# PY32MD420xx register map
Vendor: Puya; Series: PY32M; File version: 1.0.0
CPU: CM0+ r0p1, little endian, no MPU, no FPU, 4 interrupt priority bits
Registers are 32-bit, read-write, reset 0x0 unless marked. A register's access mark holds for its fields unless they carry their own. Offsets are from the block's base; [hi:lo] are bit positions; lines under a group give offsets from that group; {n}, {i} and the like mark numbered series; 'fields as' and 'values as' point back to an identical list.

## ADC — Analog to Digital Converter
Base 0x40012400
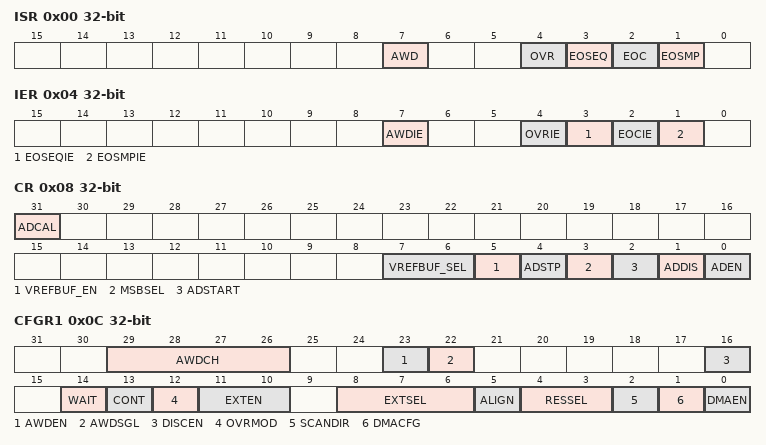
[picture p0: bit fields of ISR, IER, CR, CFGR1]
0x00 ISR — ADC interrupt and status register
  [7] AWD — ADC analog watchdog flag
  [4] OVR — ADC group regular overrun flag
  [3] EOSEQ — ADC group regular end of sequence conversions flag
  [2] EOC — ADC group regular end of unitary conversion flag
  [1] EOSMP — ADC group regular end of sampling flag
0x04 IER — ADC interrupt enable register
  [7] AWDIE — ADC analog watchdog interrupt
  [4] OVRIE — ADC group regular overrun interrupt
  [3] EOSEQIE — ADC group regular end of sequence conversions interrupt
  [2] EOCIE — ADC group regular end of unitary conversion interrupt
  [1] EOSMPIE — ADC group regular end of sampling interrupt
0x08 CR — ADC control register
  [31] ADCAL — ADC group regular conversion calibration
  [7:6] VREFBUF_SEL — ADC VrefBuffer output voltage select
    1=0; 2=1
  [5] VREFBUF_EN — ADC VrefBuffer enable
  [4] ADSTP — ADC group regular conversion stop
  [3] MSBSEL — ADC resolution highest bit conversion time control
  [2] ADSTART — ADC group regular conversion start
  [1] ADDIS — ADC disable
  [0] ADEN — ADC enable
0x0C CFGR1 — ADC configuration register 1
  [29:26] AWDCH — ADC analog watchdog monitored channel selection
    1=0; 2=1; 4=2; 8=3
  [23] AWDEN — ADC analog watchdog enable on scope ADC group regular
  [22] AWDSGL — ADC analog watchdog monitoring a single channel or all channels
  [16] DISCEN — ADC group regular sequencer discontinuous mode
  [14] WAIT — Wait conversion mode
  [13] CONT — ADC group regular continuous conversion mode
  [12] OVRMOD — ADC group regular overrun configuration
  [11:10] EXTEN — ADC group regular external trigger polarity
    1=0; 2=1
  [8:6] EXTSEL — ADC group regular external trigger source
    1=0; 2=1; 4=2
  [5] ALIGN — ADC data alignement
  [4:3] RESSEL — ADC data resolution
    1=0; 2=1
  [2] SCANDIR — Scan sequence direction
  [1] DMACFG — ADC DMA transfer configuration
  [0] DMAEN — ADC DMA transfer enable
0x10 CFGR2 — ADC configuration register 2
  [31:28] CKMODE — ADC clock mode
    1=0; 2=1; 4=2; 8=3
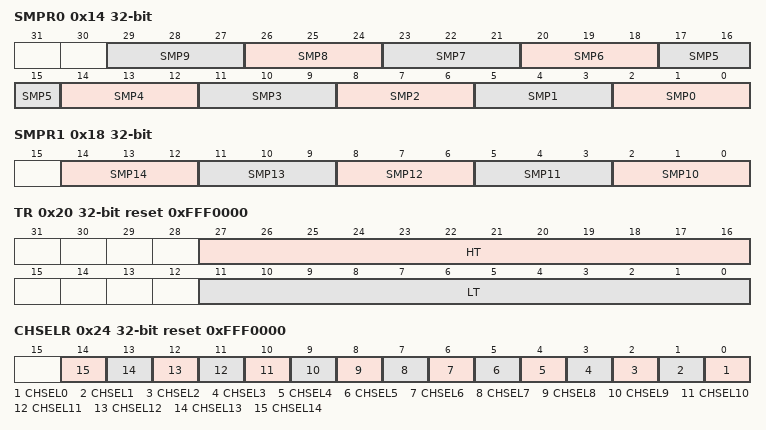
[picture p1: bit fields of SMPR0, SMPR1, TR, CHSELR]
0x14 SMPR0 — ADC sampling time register 0
  [all] fields
    1=0; 2=1; 4=2
  [3n+2:3n] SMP{n} (n=0..9) — Sampling time selection
0x18 SMPR1 — ADC sampling time register 1
  [all] fields
    1=0; 2=1; 4=2
  [3n-28:3n-30] SMP{n} (n=10..14) — Sampling time selection
0x20 TR reset 0xFFF0000 — ADC analog watchdog 1 threshold register
  [27:16] HT — ADC analog watchdog threshold high
    1=0; 2=1; 4=2; 8=3; 16=4; 32=5; 64=6; 128=7; 0x100=8; 0x200=9; 0x400=10; 0x800=11
  [11:0] LT — ADC analog watchdog threshold low
    values as HT
0x24 CHSELR reset 0xFFF0000 — ADC group regular sequencer register
  [n] CHSEL{n} (n=0..14) — Channel-{n} selection
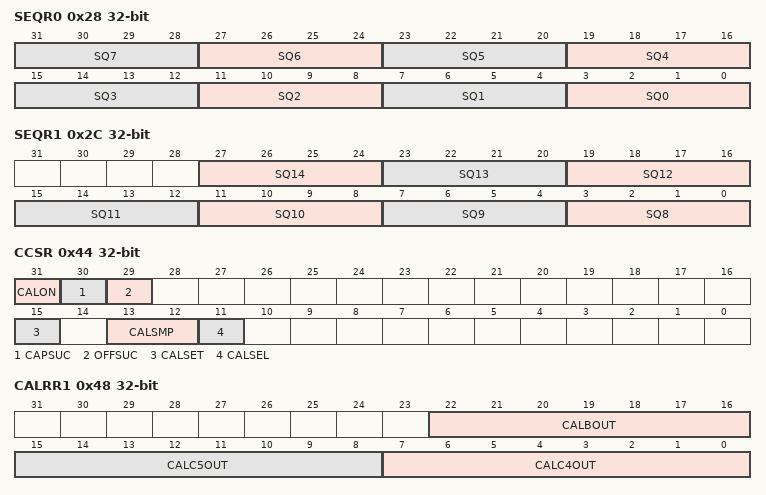
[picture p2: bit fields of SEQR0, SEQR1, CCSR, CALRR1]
0x28 SEQR0 — ADC sequence select register 0
  [all] fields
    1=0; 2=1; 4=2; 8=4
  [4n+3:4n] SQ{n} (n=0..7) — ADC sequence select
0x2C SEQR1 — ADC sequence select register 1
  [all] fields
    1=0; 2=1; 4=2; 8=4
  [4n-29:4n-32] SQ{n} (n=8..14) — ADC sequence select
0x40 DR ro — ADC group regular data register
  [15:0] DATA — ADC group regular conversion data
    1=0; 2=1; 4=2; 8=3; 16=4; 32=5; 64=6; 128=7; 0x100=8; 0x200=9; 0x400=10; 0x800=11; 0x1000=12; 0x2000=13; 0x4000=14; 0x8000=15
0x44 CCSR — ADC calibration configuration and status register
  [31] CALON ro — Calibration flag
  [30] CAPSUC — Cap calibration status flag
  [29] OFFSUC — Offset calibration status flag
  [15] CALSET — Calibration factor selection
  [13:12] CALSMP — Calibration sample time selection
    1=0; 2=1
  [11] CALSEL — Calibration contents selection
0x48 CALRR1 ro — ADC calibration result register 1
  [22:16] CALBOUT — offset result
  [15:8] CALC5OUT — C5 result
  [7:0] CALC4OUT — C4 result
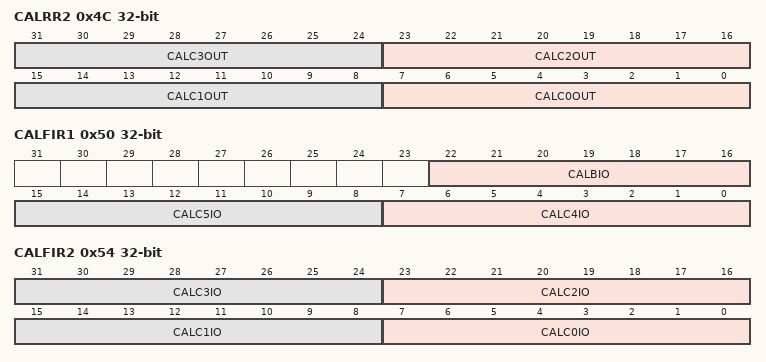
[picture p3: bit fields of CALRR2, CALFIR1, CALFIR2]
0x4C CALRR2 ro — ADC calibration result register 2
  [8n+7:8n] CALC{n}OUT (n=0..3) — C{n} result
0x50 CALFIR1 — ADC calibration factor input register 1
  [22:16] CALBIO — Calibration offset factor input
  [15:8] CALC5IO — Calibration C5 factor input
  [7:0] CALC4IO — Calibration C4 factor input
0x54 CALFIR2 — ADC calibration factor input register 2
  [8n+7:8n] CALC{n}IO (n=0..3) — Calibration C{n} factor input
0x308 CCR — ADC common configuration register
  [23] TSVREFINTEN — Temperature sensor and VREFINT enable
